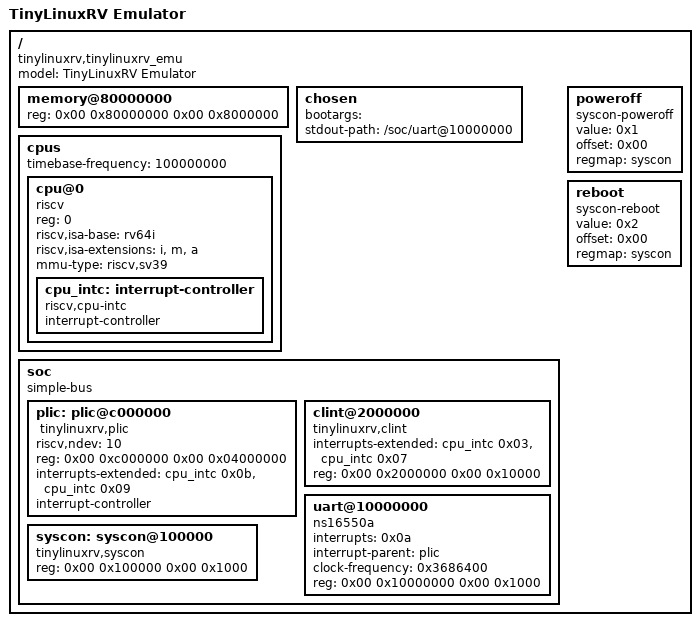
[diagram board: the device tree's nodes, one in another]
/dts-v1/;

/ {
	#address-cells = <0x02>;
	#size-cells = <0x02>;
	compatible = "tinylinuxrv,tinylinuxrv_emu";
	model = "TinyLinuxRV Emulator";

	memory@80000000 {
		device_type = "memory";
		reg = <0x00 0x80000000 0x00 0x8000000>;
	};

	chosen {
		bootargs = "";
		stdout-path = "/soc/uart@10000000";
	};

	cpus {
		#address-cells = <0x01>;
		#size-cells = <0x00>;
		timebase-frequency = <100000000>;

		cpu@0 {
			device_type = "cpu";
			reg = <0>;
			status = "okay";
			compatible = "riscv";

            riscv,isa-base = "rv64i";
            riscv,isa-extensions = "i", "m", "a";

			mmu-type = "riscv,sv39";

			cpu_intc: interrupt-controller {
				#interrupt-cells = <0x1>;
				#address-cells = <0>;
				interrupt-controller;
				compatible = "riscv,cpu-intc";
			};
		};
	};

	soc {
		#address-cells = <0x02>;
		#size-cells = <0x02>;
		compatible = "simple-bus";
		ranges;

		plic: plic@c000000 {
			#interrupt-cells = <0x1>;
			#address-cells = <0x0>;

			riscv,ndev = <10>;
			reg = <0x00 0xc000000 0x00 0x04000000>;

			interrupts-extended =
				<&cpu_intc 0x0b>,
				<&cpu_intc 0x09>;
			interrupt-controller;

			compatible = "
				tinylinuxrv,plic",
				"sifive,plic-1.0.0";
		};

		clint@2000000 {
			interrupts-extended =
				<&cpu_intc 0x03>,
				<&cpu_intc 0x07>;

			reg = <0x00 0x2000000 0x00 0x10000>;

			compatible = "tinylinuxrv,clint", "sifive,clint0";
		};

		uart@10000000 {
			interrupts = <0x0a>;
			interrupt-parent = <&plic>;
			clock-frequency = <0x3686400>;
			reg = <0x00 0x10000000 0x00 0x1000>;
			compatible = "ns16550a";
		};

		syscon: syscon@100000 {
			reg = <0x00 0x100000 0x00 0x1000>;
			compatible = "tinylinuxrv,syscon", "syscon";
		};
	};

	poweroff {
		value = <0x1>;
		offset = <0x00>;
		regmap = <&syscon>;
		compatible = "syscon-poweroff";
	};

	reboot {
		value = <0x2>;
		offset = <0x00>;
		regmap = <&syscon>;
		compatible = "syscon-reboot";
	};

};
